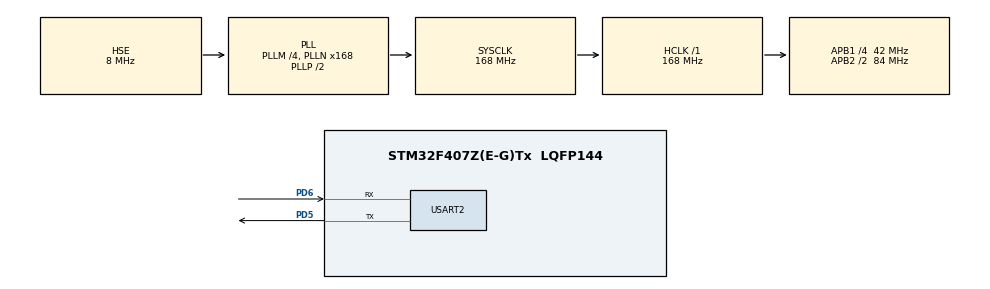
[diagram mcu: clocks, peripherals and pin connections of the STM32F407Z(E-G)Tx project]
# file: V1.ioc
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Mcu.Family=STM32F4
Mcu.Name=STM32F407Z(E-G)Tx
Mcu.Package=LQFP144
NVIC.PriorityGroup=NVIC_PRIORITYGROUP_4
NVIC.RCC_IRQn=true\:0\:0\:false\:false\:true\:true\:false\:true
PA13.Mode=Serial_Wire
PA13.Signal=SYS_JTMS-SWDIO
PA14.Mode=Serial_Wire
PA14.Signal=SYS_JTCK-SWCLK
PA8.GPIO_Speed=GPIO_SPEED_FREQ_MEDIUM
PA8.Signal=S_TIM1_CH1
PA9.GPIO_Speed=GPIO_SPEED_FREQ_MEDIUM
PA9.Signal=S_TIM1_CH2
PB6.GPIO_Speed=GPIO_SPEED_FREQ_MEDIUM
PB6.Signal=S_TIM4_CH1
PB7.GPIO_Speed=GPIO_SPEED_FREQ_MEDIUM
PB7.Signal=S_TIM4_CH2
PD5.Mode=Asynchronous
PD5.Signal=USART2_TX
PD6.Mode=Asynchronous
PD6.Signal=USART2_RX
PH0-OSC_IN.Mode=HSE-External-Oscillator
PH0-OSC_IN.Signal=RCC_OSC_IN
PH1-OSC_OUT.Mode=HSE-External-Oscillator
PH1-OSC_OUT.Signal=RCC_OSC_OUT
ProjectManager.HeapSize=0x200
ProjectManager.StackSize=0x400
ProjectManager.TargetToolchain=CMake
RCC.48MHZClocksFreq_Value=84000000
RCC.AHBFreq_Value=168000000
RCC.APB1CLKDivider=RCC_HCLK_DIV4
RCC.APB1Freq_Value=42000000
RCC.APB1TimFreq_Value=84000000
RCC.APB2CLKDivider=RCC_HCLK_DIV2
RCC.APB2Freq_Value=84000000
RCC.APB2TimFreq_Value=168000000
RCC.CortexFreq_Value=168000000
RCC.HCLKFreq_Value=168000000
RCC.HSE_VALUE=8000000
RCC.HSI_VALUE=16000000
RCC.LSE_VALUE=32768
RCC.PLLM=4
RCC.PLLN=168
RCC.PLLSourceVirtual=RCC_PLLSOURCE_HSE
RCC.SYSCLKFreq_VALUE=168000000
RCC.SYSCLKSource=RCC_SYSCLKSOURCE_PLLCLK
RCC.VCOOutputFreq_Value=336000000
SH.S_TIM1_CH1.0=TIM1_CH1
SH.S_TIM1_CH2.0=TIM1_CH2
SH.S_TIM4_CH1.0=TIM4_CH1
SH.S_TIM4_CH2.0=TIM4_CH2
USART2.VirtualMode=VM_ASYNC
board=custom

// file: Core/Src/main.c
/* USER CODE BEGIN Header */
/**
  ******************************************************************************
  * @file           : main.c
  * @brief          : STM32F407 Bootloader 主程序
  ******************************************************************************
  * @attention
  *
  * Copyright (c) 2026 STMicroelectronics.
  * All rights reserved.
  *
  * This software is licensed under terms that can be found in the LICENSE file
  * in the root directory of this software component.
  * If no LICENSE file comes with this software, it is provided AS-IS.
  *
  ******************************************************************************
  */
/* USER CODE END Header */
#include "main.h"
#include "usart.h"
#include "gpio.h"

/* USER CODE BEGIN Includes */
#include "bootloader.h"
/* USER CODE END Includes */

void SystemClock_Config(void);

int main(void)
{
  /* MCU Configuration--------------------------------------------------------*/

  /* Reset of all peripherals, Initializes the Flash interface and the Systick. */
  HAL_Init();

  /* Configure the system clock */
  SystemClock_Config();

  /* Initialize all configured peripherals */
  MX_GPIO_Init();
  MX_USART2_UART_Init();
  /* USER CODE BEGIN 2 */

  /* ================================================================
   * Bootloader 流程 (RK3588 OTA 方案):
   *   0. 上电按住 PA15 按键 -> 强制进升级模式 (兜底, 任何状态都有效)
   *   1. App 写升级标记(0x0800FC00)后软复位 -> 进入升级模式
   *      (标记保持到 RUN 成功, 传输中断电可重启继续)
   *   2. 无标记且 App 有效 -> 立即跳转 0x08010000 (不发任何信息)
   *   3. 无标记且 App 无效 -> 常驻升级模式等待固件
   * ================================================================ */
  if (BL_ButtonPressed()) {           /* 按键强制升级: 优先级最高 */
      BL_SendStr("\r\nButton held: force update mode.\r\n");
      BL_UpdateLoop();                /* 升级模式 (RUN 后清标记并跳转, 不返回) */
  }

  if (BL_UpdateFlagSet()) {
      BL_UpdateLoop();              /* 升级模式 (RUN 后清标记并跳转, 不返回) */
  }

  if (BL_AppValid()) {
      BL_JumpToApp();               /* App 有效 -> 直接跳转, 不返回 */
  }

  /* 没有有效 App, 常驻升级模式 */
  BL_SendStr("No valid app. Staying in update mode.\r\n");
  BL_UpdateLoop();

  /* USER CODE END 2 */

  /* Infinite loop */
  while (1)
  {

  }
}

void SystemClock_Config(void)
{
  RCC_OscInitTypeDef RCC_OscInitStruct = {0};
  RCC_ClkInitTypeDef RCC_ClkInitStruct = {0};

  /** Configure the main internal regulator output voltage
  */
  __HAL_RCC_PWR_CLK_ENABLE();
  __HAL_PWR_VOLTAGESCALING_CONFIG(PWR_REGULATOR_VOLTAGE_SCALE1);

  /** Initializes the RCC Oscillators according to the specified parameters
  * in the RCC_OscInitTypeDef structure.
  */
  RCC_OscInitStruct.OscillatorType = RCC_OSCILLATORTYPE_HSE;
  RCC_OscInitStruct.HSEState = RCC_HSE_ON;
  RCC_OscInitStruct.PLL.PLLState = RCC_PLL_ON;
  RCC_OscInitStruct.PLL.PLLSource = RCC_PLLSOURCE_HSE;
  RCC_OscInitStruct.PLL.PLLM = 4;
  RCC_OscInitStruct.PLL.PLLN = 168;
  RCC_OscInitStruct.PLL.PLLP = RCC_PLLP_DIV2;
  RCC_OscInitStruct.PLL.PLLQ = 4;
  if (HAL_RCC_OscConfig(&RCC_OscInitStruct) != HAL_OK)
  {
    Error_Handler();
  }

  /** Initializes the CPU, AHB and APB buses clocks
  */
  RCC_ClkInitStruct.ClockType = RCC_CLOCKTYPE_HCLK|RCC_CLOCKTYPE_SYSCLK
                              |RCC_CLOCKTYPE_PCLK1|RCC_CLOCKTYPE_PCLK2;
  RCC_ClkInitStruct.SYSCLKSource = RCC_SYSCLKSOURCE_PLLCLK;
  RCC_ClkInitStruct.AHBCLKDivider = RCC_SYSCLK_DIV1;
  RCC_ClkInitStruct.APB1CLKDivider = RCC_HCLK_DIV4;
  RCC_ClkInitStruct.APB2CLKDivider = RCC_HCLK_DIV2;

  if (HAL_RCC_ClockConfig(&RCC_ClkInitStruct, FLASH_LATENCY_5) != HAL_OK)
  {
    Error_Handler();
  }
}

void Error_Handler(void)
{
  __disable_irq();
  while (1)
  {
  }
}
